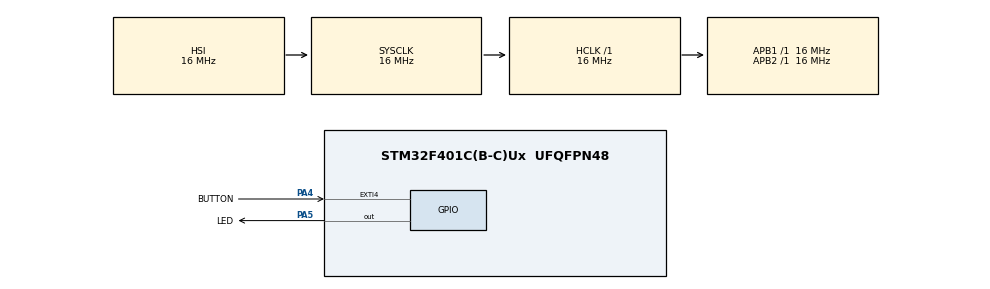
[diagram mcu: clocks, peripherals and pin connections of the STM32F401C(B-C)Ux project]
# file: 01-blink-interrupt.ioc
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Mcu.Family=STM32F4
Mcu.Name=STM32F401C(B-C)Ux
Mcu.Package=UFQFPN48
NVIC.EXTI4_IRQn=true\:0\:0\:false\:false\:true\:true\:true\:true
NVIC.PriorityGroup=NVIC_PRIORITYGROUP_4
PA4.GPIO_Label=BUTTON
PA4.GPIO_PuPd=GPIO_PULLUP
PA4.Signal=GPXTI4
PA5.GPIO_Label=LED
PA5.Signal=GPIO_Output
ProjectManager.HeapSize=0x200
ProjectManager.StackSize=0x400
ProjectManager.TargetToolchain=STM32CubeIDE
RCC.AHBFreq_Value=16000000
RCC.APB1Freq_Value=16000000
RCC.APB2Freq_Value=16000000
RCC.CortexFreq_Value=16000000
RCC.HSE_VALUE=25000000
RCC.HSI_VALUE=16000000
RCC.LSE_VALUE=32768
RCC.SYSCLKFreq_VALUE=16000000
RCC.VCOOutputFreq_Value=192000000
board=custom

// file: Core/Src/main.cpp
/* USER CODE BEGIN Header */
/**
  ******************************************************************************
  * @file           : main.c
  * @brief          : Main program body
  ******************************************************************************
  * @attention
  *
  * Copyright (c) 2026 STMicroelectronics.
  * All rights reserved.
  *
  * This software is licensed under terms that can be found in the LICENSE file
  * in the root directory of this software component.
  * If no LICENSE file comes with this software, it is provided AS-IS.
  *
  ******************************************************************************
  */
/* USER CODE END Header */
#include "main.h"

void SystemClock_Config(void);
static void MX_GPIO_Init(void);

/* USER CODE BEGIN 0 */

	// Prevents implicit conversions and defines distinct LED states
	enum class LedState { On, Off };

	// Defines state machine context
	enum class AppMode { Blink, AlwaysOn, AlwaysOff };

	// Zero-RAM compile-time config to eliminate magic numbers
	struct Config {
		static constexpr uint32_t blinkIntervalMs = 500;
		static constexpr uint32_t debounceDelayMs = 200;
	};

	// Hardware abstraction to encapsulate HAL procedural calls
	class Led {
	private:
		// Const pointer for fixed memory-mapped hardware register
		GPIO_TypeDef* const port;
		const uint16_t pin;

	public:
		// Zero-overhead compile-time instantiation
		constexpr Led(GPIO_TypeDef* p, uint16_t pin) : port(p), pin(pin) {}

		// Initial hardware state reset
		void init() {
			set(LedState::Off);
		}

		void set(LedState state) {
			HAL_GPIO_WritePin(port, pin, (state == LedState::On) ? GPIO_PIN_SET : GPIO_PIN_RESET);
		}

		void toggle() {
			HAL_GPIO_TogglePin(port, pin);
		}
	};

	// Volatile prevents CPU caching, ensuring fresh RAM reads after ISR updates
	volatile bool buttonEventPending = false;

	// extern "C" prevents C++ name mangling, allowing HAL to find the ISR callback
	extern "C" void HAL_GPIO_EXTI_Callback(uint16_t GPIO_Pin) {
		if (GPIO_Pin == BUTTON_Pin) {
			buttonEventPending = true;
		}
	}

/* USER CODE END 0 */

int main(void)
{

  /* MCU Configuration--------------------------------------------------------*/

  /* Reset of all peripherals, Initializes the Flash interface and the Systick. */
  HAL_Init();

  /* Configure the system clock */
  SystemClock_Config();

  /* Initialize all configured peripherals */
  MX_GPIO_Init();
  /* USER CODE BEGIN 2 */

	  // Statically allocate the LED object using CubeMX generated macros
		Led myLed(LED_GPIO_Port, LED_Pin);
		myLed.init();

		AppMode currentMode = AppMode::Blink;

		// Track timestamps for non-blocking timing logic
		uint32_t lastToggleTime = 0;
		uint32_t lastButtonPressTime = 0;

  /* USER CODE END 2 */

  /* Infinite loop */
  /* USER CODE BEGIN WHILE */
  while (1)
  {

	  // Fetch system tick once per iteration to ensure timing consistency across the loop
	        uint32_t currentTick = HAL_GetTick();

	        // 1. Process asynchronous hardware events (ISR flag)
	        if (buttonEventPending) {

	            // Software debouncing: discard rapid physical contact bounces
	            if (currentTick - lastButtonPressTime > Config::debounceDelayMs) {

	                // State machine transition
	                if (currentMode == AppMode::Blink) currentMode = AppMode::AlwaysOn;
	                else if (currentMode == AppMode::AlwaysOn) currentMode = AppMode::AlwaysOff;
	                else currentMode = AppMode::Blink;
	            }

	            lastButtonPressTime = currentTick;
	            buttonEventPending = false; // Acknowledge and clear the event flag
	        }

	        // 2. Execute active state logic (Non-blocking execution)
	        switch (currentMode) {
	            case AppMode::AlwaysOn:
	                myLed.set(LedState::On);
	                break;

	            case AppMode::AlwaysOff:
	                myLed.set(LedState::Off);
	                break;

	            case AppMode::Blink:
	                // Evaluates elapsed time without stalling the CPU (replaces delay())
	                if (currentTick - lastToggleTime >= Config::blinkIntervalMs) {
	                    lastToggleTime = currentTick;
	                    myLed.toggle();
	                }
	                break;
	        }
    /* USER CODE END WHILE */

  }
}

void SystemClock_Config(void)
{
  RCC_OscInitTypeDef RCC_OscInitStruct = {0};
  RCC_ClkInitTypeDef RCC_ClkInitStruct = {0};

  /** Configure the main internal regulator output voltage
  */
  __HAL_RCC_PWR_CLK_ENABLE();
  __HAL_PWR_VOLTAGESCALING_CONFIG(PWR_REGULATOR_VOLTAGE_SCALE2);

  /** Initializes the RCC Oscillators according to the specified parameters
  * in the RCC_OscInitTypeDef structure.
  */
  RCC_OscInitStruct.OscillatorType = RCC_OSCILLATORTYPE_HSI;
  RCC_OscInitStruct.HSIState = RCC_HSI_ON;
  RCC_OscInitStruct.HSICalibrationValue = RCC_HSICALIBRATION_DEFAULT;
  RCC_OscInitStruct.PLL.PLLState = RCC_PLL_NONE;
  if (HAL_RCC_OscConfig(&RCC_OscInitStruct) != HAL_OK)
  {
    Error_Handler();
  }

  /** Initializes the CPU, AHB and APB buses clocks
  */
  RCC_ClkInitStruct.ClockType = RCC_CLOCKTYPE_HCLK|RCC_CLOCKTYPE_SYSCLK
                              |RCC_CLOCKTYPE_PCLK1|RCC_CLOCKTYPE_PCLK2;
  RCC_ClkInitStruct.SYSCLKSource = RCC_SYSCLKSOURCE_HSI;
  RCC_ClkInitStruct.AHBCLKDivider = RCC_SYSCLK_DIV1;
  RCC_ClkInitStruct.APB1CLKDivider = RCC_HCLK_DIV1;
  RCC_ClkInitStruct.APB2CLKDivider = RCC_HCLK_DIV1;

  if (HAL_RCC_ClockConfig(&RCC_ClkInitStruct, FLASH_LATENCY_0) != HAL_OK)
  {
    Error_Handler();
  }
}

static void MX_GPIO_Init(void)
{
  GPIO_InitTypeDef GPIO_InitStruct = {0};

  /* GPIO Ports Clock Enable */
  __HAL_RCC_GPIOA_CLK_ENABLE();

  /*Configure GPIO pin Output Level */
  HAL_GPIO_WritePin(LED_GPIO_Port, LED_Pin, GPIO_PIN_RESET);

  /*Configure GPIO pin : BUTTON_Pin */
  GPIO_InitStruct.Pin = BUTTON_Pin;
  GPIO_InitStruct.Mode = GPIO_MODE_IT_RISING;
  GPIO_InitStruct.Pull = GPIO_PULLUP;
  HAL_GPIO_Init(BUTTON_GPIO_Port, &GPIO_InitStruct);

  /*Configure GPIO pin : LED_Pin */
  GPIO_InitStruct.Pin = LED_Pin;
  GPIO_InitStruct.Mode = GPIO_MODE_OUTPUT_PP;
  GPIO_InitStruct.Pull = GPIO_NOPULL;
  GPIO_InitStruct.Speed = GPIO_SPEED_FREQ_LOW;
  HAL_GPIO_Init(LED_GPIO_Port, &GPIO_InitStruct);

  /* EXTI interrupt init*/
  HAL_NVIC_SetPriority(EXTI4_IRQn, 0, 0);
  HAL_NVIC_EnableIRQ(EXTI4_IRQn);

}

void Error_Handler(void)
{
  __disable_irq();
  while (1)
  {
  }
}
